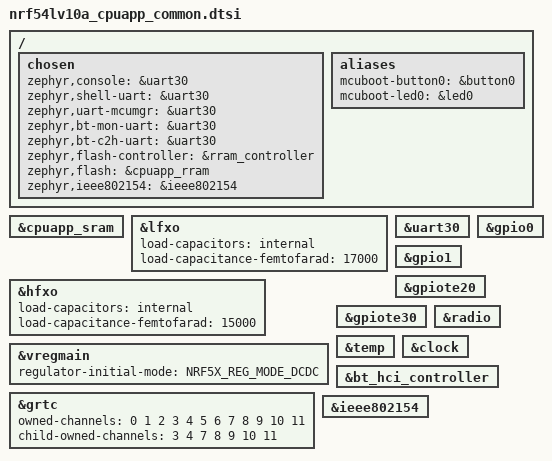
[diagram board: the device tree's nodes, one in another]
/*
 * Copyright (c) 2025 Nordic Semiconductor ASA
 *
 * SPDX-License-Identifier: Apache-2.0
 */

/* This file is common to the secure and non-secure domain */

#include <nordic/nrf54lv10a_cpuapp.dtsi>
#include "nrf54lv10dk_nrf54lv10a_common.dtsi"

/ {
	chosen {
		zephyr,console = &uart30;
		zephyr,shell-uart = &uart30;
		zephyr,uart-mcumgr = &uart30;
		zephyr,bt-mon-uart = &uart30;
		zephyr,bt-c2h-uart = &uart30;
		zephyr,flash-controller = &rram_controller;
		zephyr,flash = &cpuapp_rram;
		zephyr,ieee802154 = &ieee802154;
	};

	aliases {
		mcuboot-button0 = &button0;
		mcuboot-led0 = &led0;
	};
};

&cpuapp_sram {
	status = "okay";
};

&lfxo {
	load-capacitors = "internal";
	load-capacitance-femtofarad = <17000>;
};

&hfxo {
	load-capacitors = "internal";
	load-capacitance-femtofarad = <15000>;
};

&vregmain {
	status = "okay";
	regulator-initial-mode = <NRF5X_REG_MODE_DCDC>;
};

&grtc {
	owned-channels = <0 1 2 3 4 5 6 7 8 9 10 11>;
	/* Channels 7-11 reserved for Zero Latency IRQs, 3-4 for FLPR */
	child-owned-channels = <3 4 7 8 9 10 11>;
	status = "okay";
};

&uart30 {
	status = "okay";
};

&gpio0 {
	status = "okay";
};

&gpio1 {
	status = "okay";
};

&gpiote20 {
	status = "okay";
};

&gpiote30 {
	status = "okay";
};

&radio {
	status = "okay";
};

&temp {
	status = "okay";
};

&clock {
	status = "okay";
};

&bt_hci_controller {
	status = "okay";
};

&ieee802154 {
	status = "okay";
};
